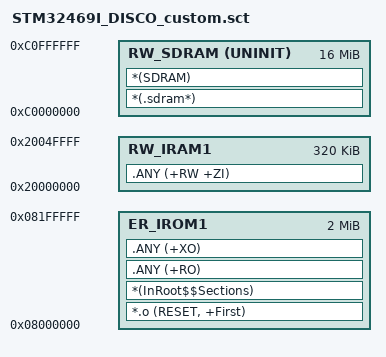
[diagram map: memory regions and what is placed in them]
; *************************************************************
; *** Custom Scatter-Loading Description (manual, do not auto-generate)
; *************************************************************

LR_IROM1 0x08000000 0x00200000  {
  ER_IROM1 0x08000000 0x00200000  {
    *.o (RESET, +First)
    *(InRoot$$Sections)
    .ANY (+RO)
    .ANY (+XO)
  }

  RW_SDRAM 0xC0000000 UNINIT 0x01000000 {
    *(.sdram*)
    *(SDRAM)
  }

  RW_IRAM1 0x20000000 0x00050000  {
    .ANY (+RW +ZI)
  }
}
